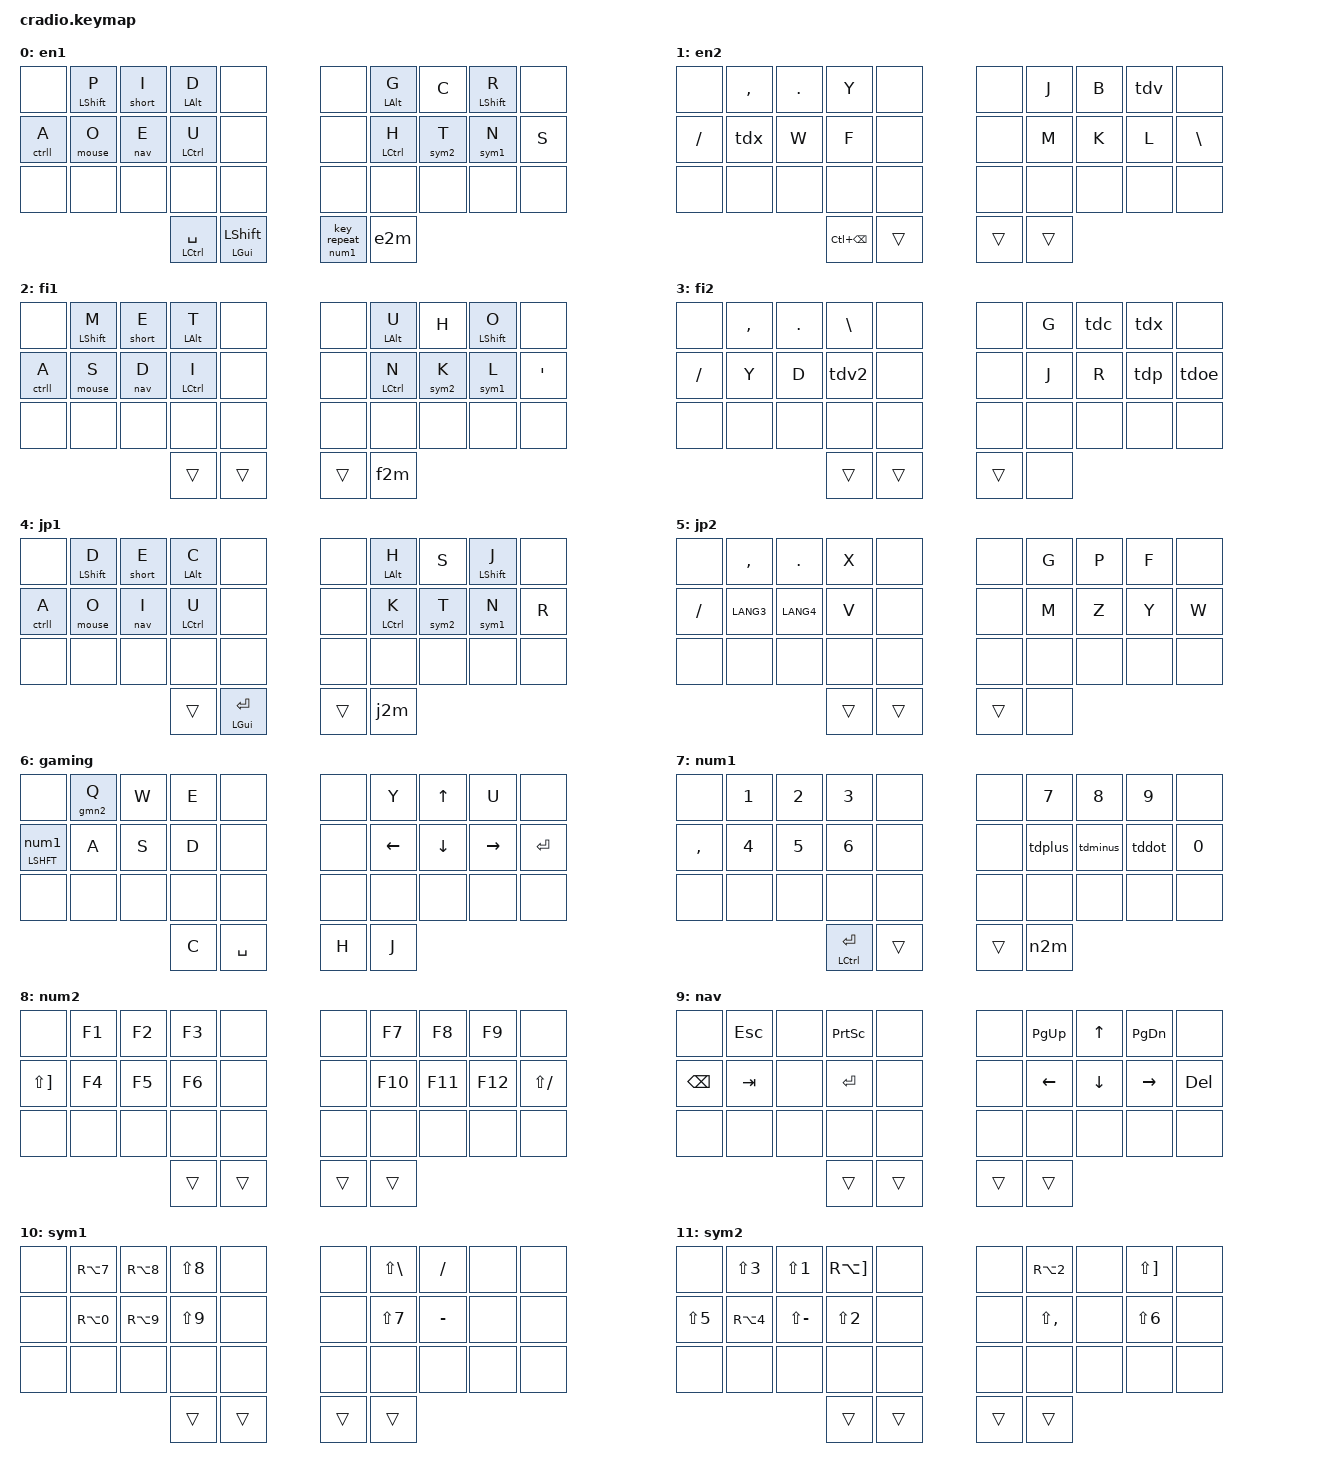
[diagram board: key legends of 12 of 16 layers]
// Copyright (c) 2022 The ZMK Contributors
// SPDX-License-Identifier: MIT

#include <behaviors.dtsi>
#include <dt-bindings/zmk/keys.h>
#include <dt-bindings/zmk/bt.h>
#include <behaviors/mouse_keys.dtsi>
#include <dt-bindings/zmk/mouse.h>

/* MOUSE */

#define U_MOUSE_MOVE_MAX 1000                     /* <--- New max speed setting (default: 600) */
#undef MOVE_UP
#undef MOVE_DOWN
#undef MOVE_LEFT
#undef MOVE_RIGHT
#define MOVE_UP MOVE_Y(-U_MOUSE_MOVE_MAX)
#define MOVE_DOWN MOVE_Y(U_MOUSE_MOVE_MAX)
#define MOVE_LEFT MOVE_X(-U_MOUSE_MOVE_MAX)
#define MOVE_RIGHT MOVE_X(U_MOUSE_MOVE_MAX)

&mmv {
    time-to-max-speed-ms = <500>;             /* <--- How long time until max speed is reached (default: 500) */
};

 &sk {
    release-after-ms = <2000>;
    quick-release;
};

#define en1 0
#define en2 1
#define fi1 2
#define fi2 3
#define jp1 4
#define jp2 5
#define gmn1 6
#define num1 7
#define num2 8
#define nav 9
#define sym1 10
#define sym2 11
#define mouse 12
#define ctrll 13
#define short 14
#define gmn2 15
#define lchng 16

/* MACROS AND BEHAVIOURS */

/ {
    macros {
        acdi: animecards_custom_definition_insertion {
            compatible = "zmk,behavior-macro";
            #binding-cells = <0>;
            bindings
                = <&macro_tap &kp NUBS &kp L &kp I &kp LS(NUBS)>
                ;
        };

        e2m: english_layer_2 {
        compatible = "zmk,behavior-macro";
        #binding-cells = <0>;
        bindings = < &sl en2>;
    };

        f2m: finnish_layer_2 {
        compatible = "zmk,behavior-macro";
        #binding-cells = <0>;
        bindings = < &sl fi2 >;
    };

        j2m: japanese_layer_2 {
        compatible = "zmk,behavior-macro";
        #binding-cells = <0>;
        bindings = < &sl jp2 >;
    };

        n2m: number_layer_2 {
        compatible = "zmk,behavior-macro";
        #binding-cells = <0>;
        bindings = < &sl num2>;
    };

    shft: shift_that_doesnt_give_duplicate_presses {
        compatible = "zmk,behavior-macro";
        #binding-cells = <0>;
        bindings = < &sk LSHFT>;
    };

        c2e: change_to_english {
        compatible = "zmk,behavior-macro";
        #binding-cells = <0>;
        bindings = 
        <&macro_press &kp LGUI>,
        <&macro_tap &kp LEFT>,
        <&macro_release &kp LGUI>,
        <&macro_tap &to en1>;
    };

        c2f: change_to_finnish {
        compatible = "zmk,behavior-macro";
        #binding-cells = <0>;
        bindings = 
        <&macro_press &kp LGUI>,
        <&macro_tap &kp LEFT>,
        <&macro_release &kp LGUI>,
        <&macro_tap &to fi1>;
    };

        c2j: change_to_japanese {
        compatible = "zmk,behavior-macro";
        #binding-cells = <0>;
        bindings = 
        <&macro_press &kp LGUI>,
        <&macro_tap &kp RIGHT>,
        <&macro_release &kp LGUI>,
        <&macro_tap &to jp1>;
    };


    };
};

/ {
    behaviors {
        ht: hold_tap {
            compatible = "zmk,behavior-hold-tap";
            #binding-cells = <2>;
            flavor = "balanced";
            tapping-term-ms = <220>;
            quick-tap-ms = <150>;
            require-prior-idle-ms = <200>;
            bindings = <&kp>, <&kp>;
        };
    
        hm: homerow_mods {
            compatible = "zmk,behavior-hold-tap";
            #binding-cells = <2>;
            tapping-term-ms = <280>;
            quick-tap-ms = <250>;
            require-prior-idle-ms = <150>;
            flavor = "tap-preferred";
            bindings = <&mo>, <&kp>;
        };
        hm2: homerow_mods2 {
            compatible = "zmk,behavior-hold-tap";
            #binding-cells = <2>;
            tapping-term-ms = <280>;
            require-prior-idle-ms = <150>;
            flavor = "tap-preferred";
            hold-while-undecided;
            bindings = <&kp>, <&kp>;
        };

        hm21: homerow_mods21 {
            compatible = "zmk,behavior-hold-tap";
            #binding-cells = <2>;
            tapping-term-ms = <280>;
            require-prior-idle-ms = <150>;
            flavor = "tap-preferred";
            bindings = <&kp>, <&sk>;
        };

        hm22: homerow_mods22 {
            compatible = "zmk,behavior-hold-tap";
            #binding-cells = <2>;
            tapping-term-ms = <280>;
            require-prior-idle-ms = <150>;
            flavor = "tap-preferred";
            bindings = <&kp>, <&kp>;
        };

        hm3: homerow_mods3 {
            compatible = "zmk,behavior-hold-tap";
            #binding-cells = <2>;
            tapping-term-ms = <200>;
            require-prior-idle-ms = <200>;
            flavor = "tap-preferred";
            bindings = <&kp>, <&shft>;
        };

        hm41: homerow_mods4_1 {
            compatible = "zmk,behavior-hold-tap";
            #binding-cells = <2>;
            tapping-term-ms = <300>;
            require-prior-idle-ms = <280>;
            flavor = "tap-preferred";
            bindings = <&kp>, <&e2m>;
        };

        hm42: homerow_mods4_2 {
            compatible = "zmk,behavior-hold-tap";
            #binding-cells = <2>;
            tapping-term-ms = <300>;
            require-prior-idle-ms = <280>;
            flavor = "tap-preferred";
            bindings = <&kp>, <&f2m>;
        };

        hm43: homerow_mods4_3 {
            compatible = "zmk,behavior-hold-tap";
            #binding-cells = <2>;
            tapping-term-ms = <300>;
            require-prior-idle-ms = <280>;
            flavor = "tap-preferred";
            bindings = <&kp>, <&j2m>;
        };  

        hm5: homerow_mods5 {
            compatible = "zmk,behavior-hold-tap";
            #binding-cells = <2>;
            tapping-term-ms = <280>;
            flavor = "tap-preferred";
            hold-while-undecided;
            bindings = <&kp>, <&mo>;  

        };  

        hm6: homerow_mods6 {
            compatible = "zmk,behavior-hold-tap";
            #binding-cells = <2>;
            tapping-term-ms = <280>;
            flavor = "hold-preferred";
            bindings = <&mo>, <&kp>;  

        };  

        hm7: homerow_mods7 {
            compatible = "zmk,behavior-hold-tap";
            #binding-cells = <2>;
            tapping-term-ms = <280>;
            quick-tap-ms = <250>;
            require-prior-idle-ms = <150>;
            flavor = "tap-preferred";
            bindings = <&mo>, <&key_repeat>;  
 };

        tdv: tap_dance_V {
            compatible = "zmk,behavior-tap-dance";
            #binding-cells = <0>;
            tapping-term-ms = <400>;
            bindings = <&kp V>, <&kp Q>;
    };

        tdx: tap_dance_X {
            compatible = "zmk,behavior-tap-dance";
            #binding-cells = <0>;
            tapping-term-ms = <500>;
            bindings = <&kp X>, <&kp Z>;
    };


        tdv2: tap_dance_V2 {
            compatible = "zmk,behavior-tap-dance";
            #binding-cells = <0>;
            tapping-term-ms = <400>;
            bindings = <&kp V>, <&kp W>;
    };

        tdp: tap_dance_P {
            compatible = "zmk,behavior-tap-dance";
            #binding-cells = <0>;
            tapping-term-ms = <400>;
            bindings = <&kp P>, <&kp B>;
    };

        tdc: tap_dance_C {
            compatible = "zmk,behavior-tap-dance";
            #binding-cells = <0>;
            tapping-term-ms = <400>;
            bindings = <&kp C>, <&kp Q>;
    };

        tdoe: tap_dance_OE {
            compatible = "zmk,behavior-tap-dance";
            #binding-cells = <0>;
            tapping-term-ms = <400>;
            bindings = <&kp SEMI>, <&kp LBKT>;
    };

        tddot: tap_dance_dot {
            compatible = "zmk,behavior-tap-dance";
            #binding-cells = <0>;
            tapping-term-ms = <400>;
            bindings = <&kp DOT>, <&kp LS(N0)>;
    };

        tdplus: tap_dance_plus {
            compatible = "zmk,behavior-tap-dance";
            #binding-cells = <0>;
            tapping-term-ms = <400>;
            bindings = <&kp MINUS>, <&kp LS(BSLH)>;
    };

        tdminus: tap_dance_minus {
            compatible = "zmk,behavior-tap-dance";
            #binding-cells = <0>;
            tapping-term-ms = <400>;
            bindings = <&kp SLASH>, <&kp LS(N7)>;
    };

 };

/* THE ACTUAL KEYMAP */

    keymap {
        compatible = "zmk,keymap";
        
        en1 {
            bindings = <
        //╭──────────┬──────────┬──────────┬──────────┬──────────╮   ╭──────────┬──────────┬──────────┬──────────┬──────────╮
        //│          │          │          │          │          │   │          │          │          │          │          │
           &none  &hm2 LSHFT P &hm short I &hm22 LALT D &none          &none     &hm22 LALT G &kp C    &hm2 LSHFT R &none
        //├──────────┼──────────┼──────────┼──────────┼──────────┤   ├──────────┼──────────┼──────────┼──────────┼──────────┤
        //│          │          │          │          │          │   │          │          │          │          │          │
        &hm ctrll A &hm mouse O &hm nav E &hm2 LCTRL U &none          &none     &hm2 LCTRL H &hm sym2 T &hm sym1 N &kp S
        //├──────────┼──────────┼──────────┼──────────┼──────────┤   ├──────────┼──────────┼──────────┼──────────┼──────────┤
        //│          │          │          │          │          │   │          │          │          │          │          │
           &none      &none      &none      &none      &none          &none      &none      &none      &none      &none
        //╰──────────┴──────────┴──────────┼──────────┼──────────┤   ├──────────┼──────────┼──────────┴──────────┴──────────╯
                                   &hm2 LCTRL SPACE &hm21 LGUI LSHIFT &hm7 num1 0 &e2m 
        //                                 ╰──────────┴──────────╯   ╰──────────┴──────────╯
            >;
        };

        en2 {
            bindings = <
        //╭──────────┬──────────┬──────────┬──────────┬──────────╮   ╭──────────┬──────────┬──────────┬──────────┬──────────╮
        //│          │          │          │          │          │   │          │          │          │          │          │
           &none      &kp COMMA  &kp DOT    &kp Y      &none          &none      &kp J      &kp B      &tdv       &none
        //├──────────┼──────────┼──────────┼──────────┼──────────┤   ├──────────┼──────────┼──────────┼──────────┼──────────┤
        //│          │          │          │          │          │   │          │          │          │          │          │
           &kp SLASH  &tdx       &kp W      &kp F      &none          &none      &kp M      &kp K      &kp L      &kp BSLH
        //├──────────┼──────────┼──────────┼──────────┼──────────┤   ├──────────┼──────────┼──────────┼──────────┼──────────┤
        //│          │          │          │          │          │   │          │          │          │          │          │
           &none      &none      &none      &none      &none          &none      &none      &none      &none      &none
        //╰──────────┴──────────┴──────────┼──────────┼──────────┤   ├──────────┼──────────┼──────────┴──────────┴──────────╯
                                            &kp LC(BSPC)  &trans     &trans         &trans     
        //                                 ╰──────────┴──────────╯   ╰──────────┴──────────╯
            >;
        };

        fi1 {
            bindings = <
        //╭──────────┬──────────┬──────────┬──────────┬──────────╮   ╭──────────┬──────────┬──────────┬──────────┬──────────╮
        //│          │          │          │          │          │   │          │          │          │          │          │
           &none    &hm2 LSHFT M &hm short E &hm2 LALT T &none         &none    &hm2 LALT U &kp H    &hm2 LSHFT O &none
        //├──────────┼──────────┼──────────┼──────────┼──────────┤   ├──────────┼──────────┼──────────┼──────────┼──────────┤
        //│          │          │          │          │          │   │          │          │          │          │          │
        &hm ctrll A &hm mouse S  &hm nav D &hm2 LCTRL I &none         &none    &hm2 LCTRL N &hm sym2 K &hm sym1 L &kp SQT
        //├──────────┼──────────┼──────────┼──────────┼──────────┤   ├──────────┼──────────┼──────────┼──────────┼──────────┤
        //│          │          │          │          │          │   │          │          │          │          │          │
           &none      &none      &none      &none      &none          &none      &none      &none      &none      &none
        //╰──────────┴──────────┴──────────┼──────────┼──────────┤   ├──────────┼──────────┼──────────┴──────────┴──────────╯
                                            &trans     &trans         &trans     &f2m
        //                                 ╰──────────┴──────────╯   ╰──────────┴──────────╯
            >;
        };

        fi2 {
            bindings = <
        //╭──────────┬──────────┬──────────┬──────────┬──────────╮   ╭──────────┬──────────┬──────────┬──────────┬──────────╮
        //│          │          │          │          │          │   │          │          │          │          │          │
           &none      &kp COMMA  &kp DOT    &kp BSLH   &none          &none      &kp G      &tdc       &tdx       &none
        //├──────────┼──────────┼──────────┼──────────┼──────────┤   ├──────────┼──────────┼──────────┼──────────┼──────────┤
        //│          │          │          │          │          │   │          │          │          │          │          │
           &kp SLASH  &kp Y      &kp D      &tdv2      &none          &none      &kp J      &kp R      &tdp       &tdoe
        //├──────────┼──────────┼──────────┼──────────┼──────────┤   ├──────────┼──────────┼──────────┼──────────┼──────────┤
        //│          │          │          │          │          │   │          │          │          │          │          │
           &none      &none      &none      &none      &none          &none      &none      &none      &none      &none
        //╰──────────┴──────────┴──────────┼──────────┼──────────┤   ├──────────┼──────────┼──────────┴──────────┴──────────╯
                                            &trans     &trans         &trans     &none
        //                                 ╰──────────┴──────────╯   ╰──────────┴──────────╯
            >;
        };

        jp1 {
            bindings = <
        //╭──────────┬──────────┬──────────┬──────────┬──────────╮   ╭──────────┬──────────┬──────────┬──────────┬──────────╮
        //│          │          │          │          │          │   │          │          │          │          │          │
           &none   &hm2 LSHFT D &hm short E &hm2 LALT C &none         &none     &hm2 LALT H &kp S    &hm2 LSHFT J &none
        //├──────────┼──────────┼──────────┼──────────┼──────────┤   ├──────────┼──────────┼──────────┼──────────┼──────────┤
        //│          │          │          │          │          │   │          │          │          │          │          │
        &hm ctrll A  &hm mouse O &hm nav I  &hm2 LCTRL U &none        &none    &hm2 LCTRL K &hm sym2 T &hm sym1 N &kp R
        //├──────────┼──────────┼──────────┼──────────┼──────────┤   ├──────────┼──────────┼──────────┼──────────┼──────────┤
        //│          │          │          │          │          │   │          │          │          │          │          │
           &none      &none      &none      &none      &none          &none      &none      &none      &none      &none
        //╰──────────┴──────────┴──────────┼──────────┼──────────┤   ├──────────┼──────────┼──────────┴──────────┴──────────╯
                                                    &trans    &hm2 LGUI RET    &trans  &j2m  
        //                                 ╰──────────┴──────────╯   ╰──────────┴──────────╯
            >;
        };

        jp2 {
            bindings = <
        //╭──────────┬──────────┬──────────┬──────────┬──────────╮   ╭──────────┬──────────┬──────────┬──────────┬──────────╮
        //│          │          │          │          │          │   │          │          │          │          │          │
           &none      &kp COMMA  &kp DOT    &kp X      &none          &none      &kp G      &kp P      &kp F       &none
        //├──────────┼──────────┼──────────┼──────────┼──────────┤   ├──────────┼──────────┼──────────┼──────────┼──────────┤
        //│          │          │          │          │          │   │          │          │          │          │          │
           &kp SLASH  &kp LANG3  &kp LANG4  &kp V      &none          &none      &kp M      &kp Z      &kp Y      &kp W
        //├──────────┼──────────┼──────────┼──────────┼──────────┤   ├──────────┼──────────┼──────────┼──────────┼──────────┤
        //│          │          │          │          │          │   │          │          │          │          │          │
           &none      &none      &none      &none      &none          &none      &none      &none      &none      &none
        //╰──────────┴──────────┴──────────┼──────────┼──────────┤   ├──────────┼──────────┼──────────┴──────────┴──────────╯
                                            &trans     &trans         &trans     &none
        //                                 ╰──────────┴──────────╯   ╰──────────┴──────────╯
            >;
        };

        gaming {
            bindings = <
        //╭──────────┬──────────┬──────────┬──────────┬──────────╮   ╭──────────┬──────────┬──────────┬──────────┬──────────╮
        //│          │          │          │          │          │   │          │          │          │          │          │
           &none     &hm6 gmn2 Q &kp W      &kp E      &none          &none      &kp Y      &kp UP     &kp U      &none
        //├──────────┼──────────┼──────────┼──────────┼──────────┤   ├──────────┼──────────┼──────────┼──────────┼──────────┤
        //│          │          │          │          │          │   │          │          │          │          │          │
       &hm LSHFT num1 &kp A      &kp S      &kp D      &none          &none      &kp LEFT   &kp DOWN   &kp RIGHT  &kp RET
        //├──────────┼──────────┼──────────┼──────────┼──────────┤   ├──────────┼──────────┼──────────┼──────────┼──────────┤
        //│          │          │          │          │          │   │          │          │          │          │          │
           &none      &none      &none      &none      &none          &none      &none      &none      &none      &none
        //╰──────────┴──────────┴──────────┼──────────┼──────────┤   ├──────────┼──────────┼──────────┴──────────┴──────────╯
                                            &kp C      &kp SPACE      &kp H      &kp J
        //                                 ╰──────────┴──────────╯   ╰──────────┴──────────╯
            >;
        };

        num1 {
            bindings = <
        //╭──────────┬──────────┬──────────┬──────────┬──────────╮   ╭──────────┬──────────┬──────────┬──────────┬──────────╮
        //│          │          │          │          │          │   │          │          │          │          │          │
           &none      &kp N1     &kp N2     &kp N3     &none          &none      &kp N7     &kp N8     &kp N9     &none
        //├──────────┼──────────┼──────────┼──────────┼──────────┤   ├──────────┼──────────┼──────────┼──────────┼──────────┤
        //│          │          │          │          │          │   │          │          │          │          │          │
           &kp COMMA  &kp N4     &kp N5     &kp N6     &none          &none      &tdplus    &tdminus   &tddot     &kp N0
        //├──────────┼──────────┼──────────┼──────────┼──────────┤   ├──────────┼──────────┼──────────┼──────────┼──────────┤
        //│          │          │          │          │          │   │          │          │          │          │          │
           &none      &none      &none      &none      &none          &none      &none      &none      &none      &none
        //╰──────────┴──────────┴──────────┼──────────┼──────────┤   ├──────────┼──────────┼──────────┴──────────┴──────────╯
                                           &hm2 LCTRL RET &trans    &trans     &n2m
        //                                 ╰──────────┴──────────╯   ╰──────────┴──────────╯
            >;
        };

        num2 {
            bindings = <
        //╭──────────┬──────────┬──────────┬──────────┬──────────╮   ╭──────────┬──────────┬──────────┬──────────┬──────────╮
        //│          │          │          │          │          │   │          │          │          │          │          │
           &none      &kp F1     &kp F2     &kp F3     &none          &none      &kp F7     &kp F8     &kp F9     &none
        //├──────────┼──────────┼──────────┼──────────┼──────────┤   ├──────────┼──────────┼──────────┼──────────┼──────────┤
        //│          │          │          │          │          │   │          │          │          │          │          │
           &kp LS(RBKT) &kp F4   &kp F5     &kp F6     &none          &none      &kp F10    &kp F11    &kp F12    &kp LS(SLASH)
        //├──────────┼──────────┼──────────┼──────────┼──────────┤   ├──────────┼──────────┼──────────┼──────────┼──────────┤
        //│          │          │          │          │          │   │          │          │          │          │          │
           &none      &none      &none      &none      &none          &none      &none      &none      &none      &none
        //╰──────────┴──────────┴──────────┼──────────┼──────────┤   ├──────────┼──────────┼──────────┴──────────┴──────────╯
                                            &trans     &trans         &trans     &trans
        //                                 ╰──────────┴──────────╯   ╰──────────┴──────────╯
            >;
        };

        nav {
            bindings = <
        //╭──────────┬──────────┬──────────┬──────────┬──────────╮   ╭──────────┬──────────┬──────────┬──────────┬──────────╮
        //│          │          │          │          │          │   │          │          │          │          │          │
           &none      &kp ESC    &none      &kp PSCRN  &none          &none      &kp PG_UP  &kp UP     &kp PG_DN  &none
        //├──────────┼──────────┼──────────┼──────────┼──────────┤   ├──────────┼──────────┼──────────┼──────────┼──────────┤
        //│          │          │          │          │          │   │          │          │          │          │          │
           &kp BSPC   &kp TAB    &none      &kp RET    &none          &none      &kp LEFT   &kp DOWN   &kp RIGHT  &kp DEL
        //├──────────┼──────────┼──────────┼──────────┼──────────┤   ├──────────┼──────────┼──────────┼──────────┼──────────┤
        //│          │          │          │          │          │   │          │          │          │          │          │
           &none      &none      &none      &none      &none          &none      &none      &none      &none      &none
        //╰──────────┴──────────┴──────────┼──────────┼──────────┤   ├──────────┼──────────┼──────────┴──────────┴──────────╯
                                            &trans     &trans         &trans     &trans
        //                                 ╰──────────┴──────────╯   ╰──────────┴──────────╯
            >;
        };

        sym1 {
            bindings = <
        //╭──────────┬──────────┬──────────┬──────────┬──────────╮   ╭──────────┬──────────┬──────────┬──────────┬──────────╮
        //│          │          │          │          │          │   │          │          │          │          │          │
           &none      &kp RA(N7) &kp RA(N8) &kp LS(N8) &none          &none    &kp LS(BSLH) &kp SLASH  &none      &none
        //├──────────┼──────────┼──────────┼──────────┼──────────┤   ├──────────┼──────────┼──────────┼──────────┼──────────┤
        //│          │          │          │          │          │   │          │          │          │          │          │
           &none      &kp RA(N0) &kp RA(N9) &kp LS(N9) &none          &none      &kp LS(N7) &kp MINUS  &none      &none
        //├──────────┼──────────┼──────────┼──────────┼──────────┤   ├──────────┼──────────┼──────────┼──────────┼──────────┤
        //│          │          │          │          │          │   │          │          │          │          │          │
           &none      &none      &none      &none      &none          &none      &none      &none      &none      &none
        //╰──────────┴──────────┴──────────┼──────────┼──────────┤   ├──────────┼──────────┼──────────┴──────────┴──────────╯
                                            &trans     &trans         &trans     &trans
        //                                 ╰──────────┴──────────╯   ╰──────────┴──────────╯
            >;
        };

        sym2 {
            bindings = <
        //╭──────────┬──────────┬──────────┬──────────┬──────────╮   ╭──────────┬──────────┬──────────┬──────────┬──────────╮
        //│          │          │          │          │          │   │          │          │          │          │          │
           &none      &kp LS(N3) &kp LS(N1) &kp RA(RBKT) &none        &none      &kp RA(N2) &none    &kp LS(RBKT) &none
        //├──────────┼──────────┼──────────┼──────────┼──────────┤   ├──────────┼──────────┼──────────┼──────────┼──────────┤
        //│          │          │          │          │          │   │          │          │          │          │          │
        &kp LS(N5) &kp RA(N4) &kp LS(MINUS) &kp LS(N2) &none          &none   &kp LS(COMMA) &none      &kp LS(N6) &none
        //├──────────┼──────────┼──────────┼──────────┼──────────┤   ├──────────┼──────────┼──────────┼──────────┼──────────┤
        //│          │          │          │          │          │   │          │          │          │          │          │
           &none      &none      &none      &none      &none          &none      &none      &none      &none      &none
        //╰──────────┴──────────┴──────────┼──────────┼──────────┤   ├──────────┼──────────┼──────────┴──────────┴──────────╯
                                            &trans     &trans         &trans     &trans
        //                                 ╰──────────┴──────────╯   ╰──────────┴──────────╯
            >;
        };

        mouse {
            bindings = <
        //╭──────────┬──────────┬──────────┬──────────┬──────────╮   ╭──────────┬──────────┬──────────┬──────────┬──────────╮
        //│          │          │          │          │          │   │          │          │          │          │          │
           &none      &none      &none      &none      &none          &none &msc SCRL_UP &mmv MOVE_UP &msc SCRL_DOWN &none
        //├──────────┼──────────┼──────────┼──────────┼──────────┤   ├──────────┼──────────┼──────────┼──────────┼──────────┤
        //│          │          │          │          │          │   │          │          │          │          │          │
           &mkp MB3   &none      &mkp MB2   &mkp MB1   &none        &none &mmv MOVE_LEFT &mmv MOVE_DOWN &mmv MOVE_RIGHT &none
        //├──────────┼──────────┼──────────┼──────────┼──────────┤   ├──────────┼──────────┼──────────┼──────────┼──────────┤
        //│          │          │          │          │          │   │          │          │          │          │          │
           &none      &none      &none      &none      &none          &none      &none      &none      &none      &none
        //╰──────────┴──────────┴──────────┼──────────┼──────────┤   ├──────────┼──────────┼──────────┴──────────┴──────────╯
                                            &trans     &trans         &trans     &trans
        //                                 ╰──────────┴──────────╯   ╰──────────┴──────────╯
            >;
        };

        ctrll {
            bindings = <
        //╭──────────┬──────────┬──────────┬──────────┬──────────╮   ╭──────────┬──────────┬──────────┬──────────┬──────────╮
        //│          │          │          │          │          │   │          │          │          │          │          │
           &none      &kp LC(Z)  &kp LC(X)  &kp LC(S)  &none          &none      &none      &none      &none      &none
        //├──────────┼──────────┼──────────┼──────────┼──────────┤   ├──────────┼──────────┼──────────┼──────────┼──────────┤
        //│          │          │          │          │          │   │          │          │          │          │          │
           &none      &kp LC(A)  &kp LC(C)  &kp LC(V)  &none          &none      &c2e       &c2f       &c2j       &to gmn1
        //├──────────┼──────────┼──────────┼──────────┼──────────┤   ├──────────┼──────────┼──────────┼──────────┼──────────┤
        //│          │          │          │          │          │   │          │          │          │          │          │
           &none      &none      &none      &none      &none          &none      &none      &none      &none      &none
        //╰──────────┴──────────┴──────────┼──────────┼──────────┤   ├──────────┼──────────┼──────────┴──────────┴──────────╯
                                            &trans     &kp LSHFT      &trans     &trans
        //                                 ╰──────────┴──────────╯   ╰──────────┴──────────╯
            >;
        };

        short {
            bindings = <
        //╭──────────┬──────────┬──────────┬──────────┬──────────╮   ╭──────────┬──────────┬──────────┬──────────┬──────────╮
        //│          │          │          │          │          │   │          │          │          │          │          │
           &none      &acdi      &none &kp LG(L)       &none          &none      &none      &none      &none      &none
        //├──────────┼──────────┼──────────┼──────────┼──────────┤   ├──────────┼──────────┼──────────┼──────────┼──────────┤
        //│          │          │          │          │          │   │          │          │          │          │          │
           &kp LC(RET) &kp LC(B) &none      &kp LC(I)  &none          &none      &none      &none      &none      &none
        //├──────────┼──────────┼──────────┼──────────┼──────────┤   ├──────────┼──────────┼──────────┼──────────┼──────────┤
        //│          │          │          │          │          │   │          │          │          │          │          │
           &none      &none      &none      &none      &none          &none      &none      &none      &none      &none
        //╰──────────┴──────────┴──────────┼──────────┼──────────┤   ├──────────┼──────────┼──────────┴──────────┴──────────╯
                                            &kp SPACE  &shft          &trans     &trans
        //                                 ╰──────────┴──────────╯   ╰──────────┴──────────╯
            >;
        };

        gaming2 {
            bindings = <
        //╭──────────┬──────────┬──────────┬──────────┬──────────╮   ╭──────────┬──────────┬──────────┬──────────┬──────────╮
        //│          │          │          │          │          │   │          │          │          │          │          │
           &none      &none      &kp LCTRL  &kp TAB    &none          &none      &none      &none      &none      &none
        //├──────────┼──────────┼──────────┼──────────┼──────────┤   ├──────────┼──────────┼──────────┼──────────┼──────────┤
        //│          │          │          │          │          │   │          │          │          │          │          │
           &kp ESC    &none      &kp R      &kp F      &none          &none      &none      &none      &none      &none
        //├──────────┼──────────┼──────────┼──────────┼──────────┤   ├──────────┼──────────┼──────────┼──────────┼──────────┤
        //│          │          │          │          │          │   │          │          │          │          │          │
           &none      &none      &none      &none      &none          &none      &none      &none      &none      &to en1
        //╰──────────┴──────────┴──────────┼──────────┼──────────┤   ├──────────┼──────────┼──────────┴──────────┴──────────╯
                                            &kp M      &kp P          &trans     &trans
        //                                 ╰──────────┴──────────╯   ╰──────────┴──────────╯
            >;
        };

    };
};

